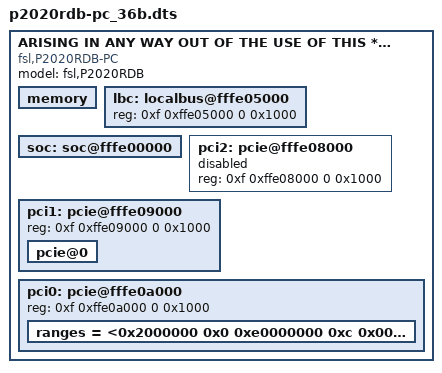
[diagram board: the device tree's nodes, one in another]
/* bench 8641.2.0 6cb9c90ef75f */
/* bench 8641.2.1 fd7c32b5dc67 */
/* bench 8641.2.2 e1cbf17e4a59 */
/* bench 8641.2.3 14446e02c149 */
/* bench 8641.2.4 50aab27073a9 */
/* bench 8641.2.5 6f9bc932c8d9 */
/* bench 8641.2.6 aa3da4653fb8 */
/* bench 8641.2.7 a58239f64d8c */
/* bench 8641.2.8 04a6da7015b5 */
/* bench 8641.2.9 907792f9ee18 */
/* bench 8641.2.10 0c4cda10722f */
/* bench 8641.2.11 f7db320779a3 */
 * P2020 RDB-PC 36Bit Physical Address Map Device Tree Source
 *
 * Copyright 2011 Freescale Semiconductor Inc.
 *
 * Redistribution and use in source and binary forms, with or without
 * modification, are permitted provided that the following conditions are met:
 *     * Redistributions of source code must retain the above copyright
 *       notice, this list of conditions and the following disclaimer.
 *     * Redistributions in binary form must reproduce the above copyright
 *       notice, this list of conditions and the following disclaimer in the
 *       documentation and/or other materials provided with the distribution.
 *     * Neither the name of Freescale Semiconductor nor the
 *       names of its contributors may be used to endorse or promote products
 *       derived from this software without specific prior written permission.
 *
 *
 * ALTERNATIVELY, this software may be distributed under the terms of the
 * GNU General Public License ("GPL") as published by the Free Software
 * Foundation, either version 2 of that License or (at your option) any
 * later version.
 *
 * THIS SOFTWARE IS PROVIDED BY Freescale Semiconductor ``AS IS'' AND ANY
 * EXPRESS OR IMPLIED WARRANTIES, INCLUDING, BUT NOT LIMITED TO, THE IMPLIED
 * WARRANTIES OF MERCHANTABILITY AND FITNESS FOR A PARTICULAR PURPOSE ARE
 * DISCLAIMED. IN NO EVENT SHALL Freescale Semiconductor BE LIABLE FOR ANY
 * DIRECT, INDIRECT, INCIDENTAL, SPECIAL, EXEMPLARY, OR CONSEQUENTIAL DAMAGES
 * (INCLUDING, BUT NOT LIMITED TO, PROCUREMENT OF SUBSTITUTE GOODS OR SERVICES;
 * LOSS OF USE, DATA, OR PROFITS; OR BUSINESS INTERRUPTION) HOWEVER CAUSED AND
 * ON ANY THEORY OF LIABILITY, WHETHER IN CONTRACT, STRICT LIABILITY, OR TORT
 * (INCLUDING NEGLIGENCE OR OTHERWISE) ARISING IN ANY WAY OUT OF THE USE OF THIS
 * SOFTWARE, EVEN IF ADVISED OF THE POSSIBILITY OF SUCH DAMAGE.
 */

/include/ "p2020si-pre.dtsi"

/ {
	model = "fsl,P2020RDB";
	compatible = "fsl,P2020RDB-PC";

	memory {
		device_type = "memory";
	};

	lbc: localbus@fffe05000 {
		reg = <0xf 0xffe05000 0 0x1000>;

		/* NOR and NAND Flashes */
		ranges = <0x0 0x0 0xf 0xef000000 0x01000000
			  0x1 0x0 0xf 0xff800000 0x00040000
			  0x2 0x0 0xf 0xffb00000 0x00020000
			  0x3 0x0 0xf 0xffa00000 0x00020000>;
	};

	soc: soc@fffe00000 {
		ranges = <0x0 0xf 0xffe00000 0x100000>;
	};

	pci2: pcie@fffe08000 {
		reg = <0xf 0xffe08000 0 0x1000>;
		status = "disabled";
	};

	pci1: pcie@fffe09000 {
		reg = <0xf 0xffe09000 0 0x1000>;
		ranges = <0x2000000 0x0 0xe0000000 0xc 0x20000000 0x0 0x20000000
			  0x1000000 0x0 0x00000000 0xf 0xffc10000 0x0 0x10000>;
		pcie@0 {
			ranges = <0x2000000 0x0 0xe0000000
				  0x2000000 0x0 0xe0000000
				  0x0 0x20000000

				  0x1000000 0x0 0x0
				  0x1000000 0x0 0x0
				  0x0 0x100000>;
		};
	};

	pci0: pcie@fffe0a000 {
		reg = <0xf 0xffe0a000 0 0x1000>;
		ranges = <0x2000000 0x0 0xe0000000 0xc 0x00000000 0x0 0x20000000
/* bench 22627.4.0 9a4faa06f6c9 */
/* bench 22627.4.1 8e094d526ec6 */
/* bench 22627.4.2 dfb34676e1d8 */
/* bench 22627.4.3 af9562e0556c */
/* bench 22627.4.4 6cb9f326102d */
/* bench 22627.4.5 4a24e047b362 */
/* bench 22627.4.6 05586db40fc5 */
		pcie@0 {
			ranges = <0x2000000 0x0 0xe0000000
				  0x2000000 0x0 0xe0000000
				  0x0 0x20000000

				  0x1000000 0x0 0x0
				  0x1000000 0x0 0x0
				  0x0 0x100000>;
		};
	};
};

/include/ "p2020rdb-pc.dtsi"
/* bench 14657.3.0 20eff53b96c2 */
/* bench 14657.3.1 7813098e6914 */
/* bench 14657.3.2 76231aaca918 */
/* bench 14657.3.3 574d765e73ad */
/* bench 14657.3.4 1c9bda2e01cf */
/* bench 14657.3.5 28079c474cb7 */
/* bench 14657.3.6 4ea0c4cc51f3 */
/* bench 14657.3.7 6e01d6349116 */
/* bench 14657.3.8 6c7d5ba3bf50 */
/* bench 14657.3.9 c46a199367a5 */
/* bench 14657.3.10 67bd6cc1e891 */
